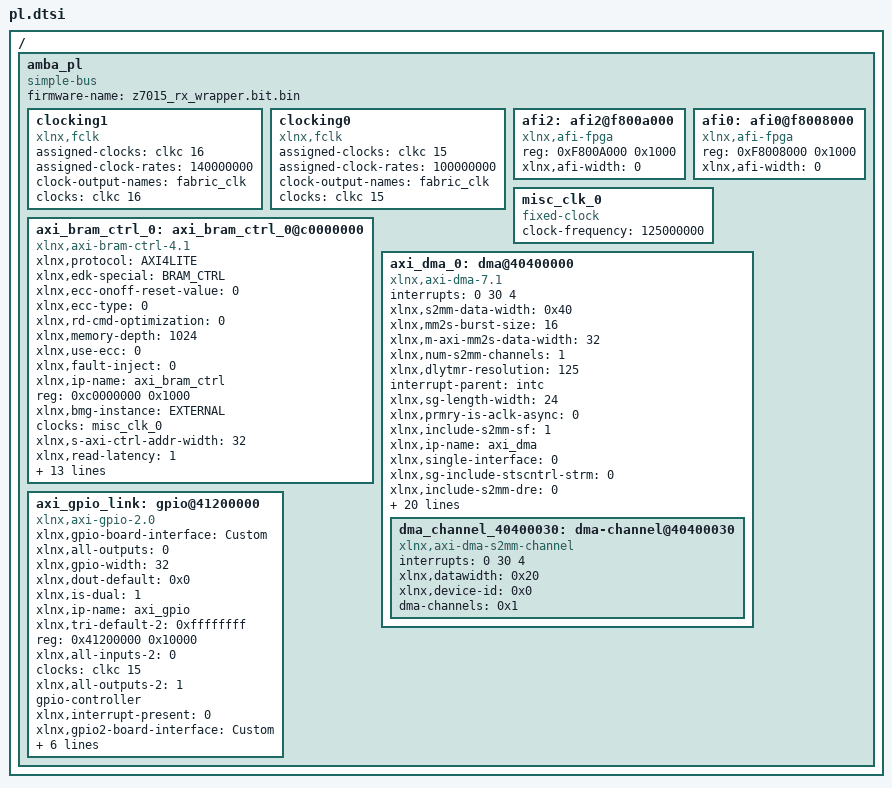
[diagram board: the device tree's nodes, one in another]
/ {
	amba_pl: amba_pl {
		ranges;
		compatible = "simple-bus";
		#address-cells = <1>;
		#size-cells = <1>;
		firmware-name = "z7015_rx_wrapper.bit.bin";
		clocking1: clocking1 {
			compatible = "xlnx,fclk";
			assigned-clocks = <&clkc 16>;
			assigned-clock-rates = <140000000>;
			#clock-cells = <0>;
			clock-output-names = "fabric_clk";
			clocks = <&clkc 16>;
		};
		clocking0: clocking0 {
			compatible = "xlnx,fclk";
			assigned-clocks = <&clkc 15>;
			assigned-clock-rates = <100000000>;
			#clock-cells = <0>;
			clock-output-names = "fabric_clk";
			clocks = <&clkc 15>;
		};
		afi2: afi2@f800a000 {
			status = "okay";
			compatible = "xlnx,afi-fpga";
			#address-cells = <1>;
			reg = <0xF800A000 0x1000>;
			#size-cells = <0>;
			xlnx,afi-width = <0>;
		};
		afi0: afi0@f8008000 {
			status = "okay";
			compatible = "xlnx,afi-fpga";
			#address-cells = <1>;
			reg = <0xF8008000 0x1000>;
			#size-cells = <0>;
			xlnx,afi-width = <0>;
		};
		misc_clk_0: misc_clk_0 {
			compatible = "fixed-clock";
			clock-frequency = <125000000>;
			#clock-cells = <0>;
		};
		axi_bram_ctrl_0: axi_bram_ctrl_0@c0000000 {
			xlnx,protocol = "AXI4LITE";
			xlnx,edk-special = "BRAM_CTRL";
			compatible = "xlnx,axi-bram-ctrl-4.1" , "xlnx,axi-bram-ctrl";
			xlnx,ecc-onoff-reset-value = <0>;
			xlnx,ecc-type = <0>;
			xlnx,rd-cmd-optimization = <0>;
			xlnx,memory-depth = <1024>;
			xlnx,use-ecc = <0>;
			xlnx,fault-inject = <0>;
			xlnx,ip-name = "axi_bram_ctrl";
			reg = <0xc0000000 0x1000>;
			xlnx,bmg-instance = "EXTERNAL";
			clocks = <&misc_clk_0>;
			xlnx,s-axi-ctrl-addr-width = <32>;
			xlnx,read-latency = <1>;
			xlnx,id-width = <0>;
			xlnx,s-axi-supports-narrow-burst = <0>;
			xlnx,supports-narrow-burst = <0>;
			xlnx,single-port-bram = <1>;
			xlnx,ecc = <0>;
			xlnx,edk-iptype = "PERIPHERAL";
			status = "okay";
			clock-names = "s_axi_aclk";
			xlnx,data-width = <32>;
			xlnx,bram-addr-width = <10>;
			xlnx,bram-inst-mode = "EXTERNAL";
			xlnx,s-axi-ctrl-data-width = <32>;
			xlnx,mem-depth = <1024>;
			xlnx,s-axi-id-width = <1>;
			xlnx,name = "axi_bram_ctrl_0";
		};
		axi_dma_0: dma@40400000 {
			interrupts = < 0 30 4 >;
			compatible = "xlnx,axi-dma-7.1" , "xlnx,axi-dma-1.00.a";
			xlnx,s2mm-data-width = <0x40>;
			xlnx,mm2s-burst-size = <16>;
			xlnx,m-axi-mm2s-data-width = <32>;
			xlnx,num-s2mm-channels = <1>;
			xlnx,dlytmr-resolution = <125>;
			interrupt-parent = <&intc>;
			xlnx,sg-length-width = <24>;
			xlnx,prmry-is-aclk-async = <0>;
			xlnx,include-s2mm-sf = <1>;
			#dma-cells = <1>;
			xlnx,ip-name = "axi_dma";
			xlnx,single-interface = <0>;
			xlnx,sg-include-stscntrl-strm = <0>;
			xlnx,include-s2mm-dre = <0>;
			reg = <0x40400000 0x10000>;
			xlnx,addr-width = <32>;
			xlnx,include-s2mm = <1>;
			clocks = <&clkc 15>, <&clkc 15>;
			xlnx,s-axis-s2mm-tdata-width = <32>;
			xlnx,micro-dma = <0>;
			xlnx,increase-throughput = <0>;
			xlnx,mm2s-data-width = <0x20>;
			xlnx,addrwidth = <0x20>;
			xlnx,sg-use-stsapp-length = <0>;
			xlnx,m-axis-mm2s-tdata-width = <32>;
			xlnx,edk-iptype = "PERIPHERAL";
			xlnx,s2mm-burst-size = <64>;
			xlnx,m-axi-s2mm-data-width = <64>;
			xlnx,num-mm2s-channels = <1>;
			xlnx,enable-multi-channel = <0>;
			status = "okay";
			xlnx,include-mm2s-sf = <1>;
			clock-names = "m_axi_s2mm_aclk" , "s_axi_lite_aclk";
			interrupt-names = "s2mm_introut";
			xlnx,include-mm2s = <0>;
			xlnx,include-mm2s-dre = <0>;
			xlnx,name = "axi_dma_0";
			dma_channel_40400030: dma-channel@40400030 {
				interrupts = <0 30 4>;
				xlnx,datawidth = <0x20>;
				xlnx,device-id = <0x0>;
				compatible = "xlnx,axi-dma-s2mm-channel";
				dma-channels = <0x1>;
			};
		};
		axi_gpio_link: gpio@41200000 {
			xlnx,gpio-board-interface = "Custom";
			compatible = "xlnx,axi-gpio-2.0" , "xlnx,xps-gpio-1.00.a";
			xlnx,all-outputs = <0>;
			#gpio-cells = <2>;
			xlnx,gpio-width = <32>;
			xlnx,dout-default = <0x0>;
			xlnx,is-dual = <1>;
			xlnx,ip-name = "axi_gpio";
			xlnx,tri-default-2 = <0xffffffff>;
			reg = <0x41200000 0x10000>;
			xlnx,all-inputs-2 = <0>;
			clocks = <&clkc 15>;
			xlnx,all-outputs-2 = <1>;
			gpio-controller;
			xlnx,interrupt-present = <0>;
			xlnx,gpio2-board-interface = "Custom";
			xlnx,edk-iptype = "PERIPHERAL";
			xlnx,dout-default-2 = <0x1>;
			status = "okay";
			xlnx,gpio2-width = <32>;
			clock-names = "s_axi_aclk";
			xlnx,tri-default = <0xffffffff>;
			xlnx,name = "axi_gpio_link";
			xlnx,all-inputs = <1>;
		};
	};
};
